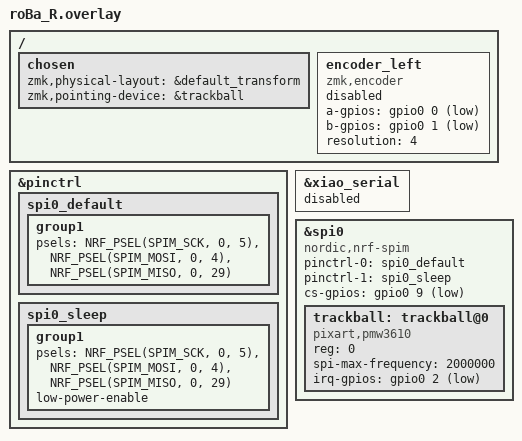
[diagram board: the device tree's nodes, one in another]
#include "roBa.dtsi"

 / {
    chosen {
        zmk,physical-layout = &default_transform;
        zmk,pointing-device = &trackball;   /* PMW3610 を使う */
    };
};

/* SPI0 ピン割り当て（<>の中は数値のみ） */
&pinctrl {
    spi0_default: spi0_default {
        group1 {
            psels = <NRF_PSEL(SPIM_SCK,  0, 5)>,
                    <NRF_PSEL(SPIM_MOSI, 0, 4)>,
                    <NRF_PSEL(SPIM_MISO, 0, 29)>;
        };
    };
    spi0_sleep: spi0_sleep {
        group1 {
            psels = <NRF_PSEL(SPIM_SCK,  0, 5)>,
                    <NRF_PSEL(SPIM_MOSI, 0, 4)>,
                    <NRF_PSEL(SPIM_MISO, 0, 29)>;
            low-power-enable;
        };
    };
};  /* ←セミコロン必須 */

/* 未使用なら無効 */
&xiao_serial { status = "disabled"; };

/* PMW3610 本体（★ `cpi` は削除。Kconfigで設定する） */
&spi0 {
    status = "okay";
    compatible = "nordic,nrf-spim";
    pinctrl-0 = <&spi0_default>;
    pinctrl-1 = <&spi0_sleep>;
    pinctrl-names = "default", "sleep";
    cs-gpios = <&gpio0 9 GPIO_ACTIVE_LOW>;

    trackball: trackball@0 {
        status = "okay";
        compatible = "pixart,pmw3610";
        reg = <0>;
        spi-max-frequency = <2000000>;
        irq-gpios = <&gpio0 2 GPIO_ACTIVE_LOW>;
        /* label はあっても無くてもOK。cpi は書かない */
        // label = "PMW3610";
    };
};

/* 右ビルドで keymap の &encoder_left を満たすダミー（無効） */
 / {
    encoder_left: encoder_left {
        compatible = "zmk,encoder";
        a-gpios = <&gpio0 0 GPIO_ACTIVE_LOW>;
        b-gpios = <&gpio0 1 GPIO_ACTIVE_LOW>;
        resolution = <4>;
        status = "disabled";
    };
};
